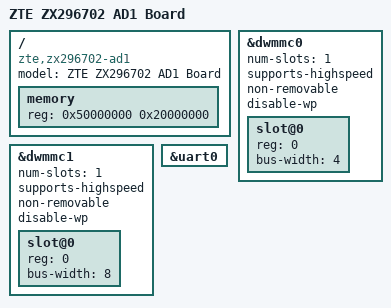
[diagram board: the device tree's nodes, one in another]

/dts-v1/;

#include "zx296702.dtsi"

/ {
	model = "ZTE ZX296702 AD1 Board";
	compatible = "zte,zx296702-ad1", "zte,zx296702";

	memory {
		reg = <0x50000000 0x20000000>;
	};
};

&dwmmc0 {
	num-slots = <1>;
	supports-highspeed;
	non-removable;
	disable-wp;
	status = "okay";

	slot@0 {
		reg = <0>;
		bus-width = <4>;
	};
};

&dwmmc1 {
	num-slots = <1>;
	supports-highspeed;
	non-removable;
	disable-wp;
	status = "okay";

	slot@0 {
		reg = <0>;
		bus-width = <8>;
	};
};

&uart0 {
	status = "okay";
};
